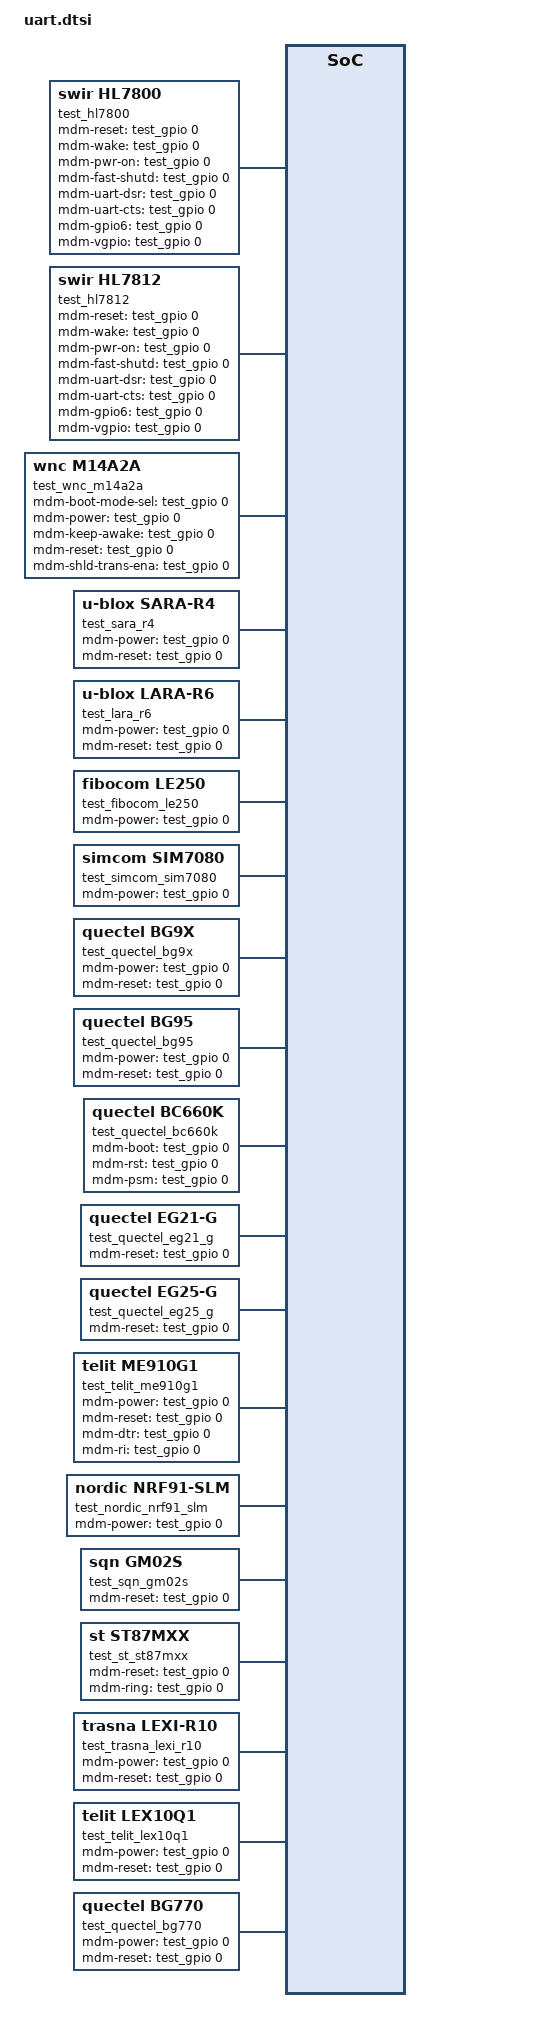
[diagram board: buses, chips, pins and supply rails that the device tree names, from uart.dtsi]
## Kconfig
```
# Copyright (c) 2021 Linaro Limited
# SPDX-License-Identifier: Apache-2.0

source "Kconfig.zephyr"

# Modem Kconfig depends on SERIAL_SUPPORT_INTERRUPT so
# fake out Kconfig for testing purposes.

config TEST_UART
	bool "Test UART"
	select SERIAL_HAS_DRIVER
	select SERIAL_SUPPORT_INTERRUPT
```

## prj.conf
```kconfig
CONFIG_NET_NAMESPACE_COMPAT_MODE=n
```

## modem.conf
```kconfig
CONFIG_TEST=y
CONFIG_TEST_RANDOM_GENERATOR=y
CONFIG_TEST_USERSPACE=y
CONFIG_SERIAL=y
CONFIG_NETWORKING=y
CONFIG_NET_IPV4=y
CONFIG_MODEM=y
CONFIG_MODEM_HL7800=y
CONFIG_MODEM_HL7800_FW_UPDATE=y
CONFIG_MODEM_HL7800_SET_APN_NAME_ON_STARTUP=y
CONFIG_MODEM_HL7800_APN_NAME="internet"
CONFIG_MODEM_HL7800_RAT_M1=y
CONFIG_MODEM_WNCM14A2A=y
```

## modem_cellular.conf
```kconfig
CONFIG_GPIO=y
CONFIG_SERIAL=y
CONFIG_MODEM=y
CONFIG_NETWORKING=y
CONFIG_NET_L2_PPP=y
CONFIG_PM_DEVICE=y
CONFIG_MODEM_CELLULAR=y
CONFIG_UART_ASYNC_API=y
```

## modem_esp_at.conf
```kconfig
CONFIG_GPIO=y
CONFIG_SERIAL=y
CONFIG_MODEM=y
CONFIG_NETWORKING=y
CONFIG_NET_SOCKETS=y
CONFIG_NET_IPV4=y
CONFIG_WIFI=y
CONFIG_WIFI_ESP_AT_CIPDINFO_USE=y
CONFIG_NET_CONNECTION_MANAGER=y
CONFIG_NET_CONNECTION_MANAGER_CONNECTIVITY_WIFI_MGMT=y
```

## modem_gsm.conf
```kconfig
CONFIG_GPIO=y
CONFIG_SERIAL=y
CONFIG_MODEM=y
CONFIG_NETWORKING=y
CONFIG_NET_IPV4=y
CONFIG_NET_DRIVERS=y
CONFIG_NET_PPP=y
CONFIG_NET_L2_PPP=y
CONFIG_MODEM_GSM_PPP=y
```

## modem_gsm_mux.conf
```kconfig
CONFIG_GPIO=y
CONFIG_SERIAL=y
CONFIG_MODEM=y
CONFIG_NETWORKING=y
CONFIG_NET_IPV4=y
CONFIG_NET_DRIVERS=y
CONFIG_NET_PPP=y
CONFIG_NET_L2_PPP=y
CONFIG_MODEM_GSM_PPP=y
CONFIG_GSM_MUX=y
CONFIG_UART_MUX=y
```

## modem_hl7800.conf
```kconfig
CONFIG_GPIO=y
CONFIG_SERIAL=y
CONFIG_MODEM=y
CONFIG_NETWORKING=y
CONFIG_NET_IPV4=y
CONFIG_NET_IPV6=y
CONFIG_MODEM_HL7800=y
CONFIG_MODEM_HL7800_FW_UPDATE=y
CONFIG_MODEM_HL7800_SET_APN_NAME_ON_STARTUP=y
CONFIG_MODEM_HL7800_APN_NAME="internet"
CONFIG_MODEM_HL7800_RAT_M1=y
CONFIG_MODEM_WNCM14A2A=y
```

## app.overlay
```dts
/*
 * Copyright (c) 2020, Linaro Ltd.
 *
 * SPDX-License-Identifier: Apache-2.0
 *
 * Application overlay for testing driver builds
 *
 * Names in this file should be chosen in a way that won't conflict
 * with real-world devicetree nodes, to allow these tests to run on
 * (and be extended to test) real hardware.
 */

/ {
	test {
		#address-cells = <1>;
		#size-cells = <1>;

		test_uart: uart@55556666 {
			compatible = "vnd,serial";
			reg = <0x55556666 0x1000>;
			status = "okay";

#include "uart.dtsi"
		};

		test_gpio: gpio@deadbeef {
			compatible = "vnd,gpio";
			reg = <0xdeadbeef 0x1000>;
			gpio-controller;
			#gpio-cells = <0x2>;
			status = "okay";
		};
	};

	test_sim_mux: test-sim-mux {
		compatible = "gpio-mux";
		#mux-control-cells = <0>;
		#mux-state-cells = <1>;
		mux-gpios = <&test_gpio 1 0>;
	};
};
```

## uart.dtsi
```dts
/*
 * Copyright (c) 2020, Linaro Ltd.
 *
 * SPDX-License-Identifier: Apache-2.0
 *
 * Application overlay for uart devices
 */

test_hl7800: hl7800 {
	compatible = "swir,hl7800";
	mdm-reset-gpios = <&test_gpio 0 0>;
	mdm-wake-gpios = <&test_gpio 0 0>;
	mdm-pwr-on-gpios = <&test_gpio 0 0>;
	mdm-fast-shutd-gpios = <&test_gpio 0 0>;
	mdm-uart-dsr-gpios = <&test_gpio 0 0>;
	mdm-uart-cts-gpios = <&test_gpio 0 0>;
	mdm-gpio6-gpios = <&test_gpio 0 0>;
	mdm-vgpio-gpios = <&test_gpio 0 0>;

	test_hl7800_socket_offload: socket_offload {
		compatible = "swir,hl7800-offload", "swir,hl78xx-offload";
		max-data-length = <512>;
	};

	test_hl7800_gnss: hl_gnss {
		compatible = "swir,hl7800-gnss", "swir,hl78xx-gnss";
		pps-mode = "GNSS_PPS_MODE_DISABLED";
		fix-rate = <1000>;
	};
};

test_hl7812: hl7812 {
	compatible = "swir,hl7812";
	mdm-reset-gpios = <&test_gpio 0 0>;
	mdm-wake-gpios = <&test_gpio 0 0>;
	mdm-pwr-on-gpios = <&test_gpio 0 0>;
	mdm-fast-shutd-gpios = <&test_gpio 0 0>;
	mdm-uart-dsr-gpios = <&test_gpio 0 0>;
	mdm-uart-cts-gpios = <&test_gpio 0 0>;
	mdm-gpio6-gpios = <&test_gpio 0 0>;
	mdm-vgpio-gpios = <&test_gpio 0 0>;

	test_hl7812_socket_offload: socket_offload {
		compatible = "swir,hl7812-offload";
		max-data-length = <512>;
	};

	test_hl7812_gnss: hl_gnss {
		compatible = "swir,hl7812-gnss";
		pps-mode = "GNSS_PPS_MODE_DISABLED";
		fix-rate = <1000>;
	};
};

test_wnc_m14a2a: wncm14a2a {
	compatible = "wnc,m14a2a";
	mdm-boot-mode-sel-gpios = <&test_gpio 0 0>;
	mdm-power-gpios = <&test_gpio 0 0>;
	mdm-keep-awake-gpios = <&test_gpio 0 0>;
	mdm-reset-gpios = <&test_gpio 0 0>;
	mdm-shld-trans-ena-gpios = <&test_gpio 0 0>;
};

test_sara_r4: sara_r4 {
	compatible = "u-blox,sara-r4";

	mdm-power-gpios = <&test_gpio 0 0>;
	mdm-reset-gpios = <&test_gpio 0 0>;
};

test_lara_r6: lara_r6 {
	compatible = "u-blox,lara-r6";

	mdm-power-gpios = <&test_gpio 0 0>;
	mdm-reset-gpios = <&test_gpio 0 0>;
};

test_fibocom_le250: fibocom_le250 {
	compatible = "fibocom,le250";

	mdm-power-gpios = <&test_gpio 0 0>;
};

test_simcom_sim7080: sim7080 {
	compatible = "simcom,sim7080";

	mdm-power-gpios = <&test_gpio 0 0>;
};

test_quectel_bg9x: quectel_bg9x {
	compatible = "quectel,bg9x";

	mdm-power-gpios = <&test_gpio 0 0>;
	mdm-reset-gpios = <&test_gpio 0 0>;
};

test_quectel_bg95: quectel_bg95 {
	compatible = "quectel,bg95";

	mdm-power-gpios = <&test_gpio 0 0>;
	mdm-reset-gpios = <&test_gpio 0 0>;

	sim-slots {
		compatible = "modem-sims";
		#address-cells = <1>;
		#size-cells = <0>;

		sim-slot@0 {
			reg = <0>;
			mux-states = <&test_sim_mux 0>;
		};

		sim-slot@1 {
			reg = <1>;
			mux-states = <&test_sim_mux 1>;
			default-sim;
		};
	};
};

test_quectel_bc660k: bc660k {
	compatible = "quectel,bc660k";

	mdm-boot-gpios = <&test_gpio 0 0>;
	mdm-rst-gpios = <&test_gpio 0 0>;
	mdm-psm-gpios = <&test_gpio 0 0>;
};

test_quectel_eg21_g: quectel_eg21_g {
	compatible = "quectel,eg21-g";

	mdm-reset-gpios = <&test_gpio 0 0>;
};

test_quectel_eg25_g: quectel_eg25_g {
	compatible = "quectel,eg25-g";

	mdm-reset-gpios = <&test_gpio 0 0>;
};

test_telit_me910g1: telit_me910g1 {
	compatible = "telit,me910g1";

	mdm-power-gpios = <&test_gpio 0 0>;
	mdm-reset-gpios = <&test_gpio 0 0>;

	mdm-dtr-gpios = <&test_gpio 0 0>;
	mdm-ri-gpios = <&test_gpio 0 0>;
};

test_esp_at: esp_at {
	compatible = "espressif,esp-at";
};

test_nordic_nrf91_slm: nordic_nrf91_slm {
	compatible = "nordic,nrf91-slm";

	mdm-power-gpios = <&test_gpio 0 0>;
};

test_nordic_nrf91_sm_v2: nordic_nrf91_sm_v2 {
	compatible = "nordic,nrf91-sm-v2";
};

test_sqn_gm02s: sqn_gm02s {
	compatible = "sqn,gm02s";

	mdm-reset-gpios = <&test_gpio 0 0>;
};

test_st_st87mxx: st87mxx {
	compatible = "st,st87mxx";

	mdm-reset-gpios = <&test_gpio 0 0>;
	mdm-ring-gpios = <&test_gpio 0 0>;
};

test_trasna_lexi_r10: trasna_lexi_r10 {
	compatible = "trasna,lexi-r10";

	mdm-power-gpios = <&test_gpio 0 0>;
	mdm-reset-gpios = <&test_gpio 0 0>;
};

test_telit_lex10q1: telit_lex10q1 {
	compatible = "telit,lex10q1";

	mdm-power-gpios = <&test_gpio 0 0>;
	mdm-reset-gpios = <&test_gpio 0 0>;
};

test_quectel_bg770: quectel_bg770 {
	compatible = "quectel,bg770";

	mdm-power-gpios = <&test_gpio 0 0>;
	mdm-reset-gpios = <&test_gpio 0 0>;
};
```

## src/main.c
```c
/*
 * Copyright (c) 2012-2014 Wind River Systems, Inc.
 *
 * SPDX-License-Identifier: Apache-2.0
 */

#include <zephyr/device.h>
#include <zephyr/toolchain.h>

#ifdef CONFIG_MODEM_CELLULAR
#include <zephyr/modem/chat.h>
#include <zephyr/drivers/modem/modem_cellular.h>

/* Validate the board-init registration macro expands, links, and binds a
 * board-supplied chat script to a modem instance.
 */
MODEM_CHAT_MATCH_DEFINE(board_init_ok_match, "OK", "", NULL);
MODEM_CHAT_SCRIPT_CMDS_DEFINE(board_init_script_cmds,
			      MODEM_CHAT_SCRIPT_CMD_RESP("AT", board_init_ok_match));
MODEM_CHAT_SCRIPT_NO_ABORT_DEFINE(board_init_script, board_init_script_cmds, NULL, 4);
MODEM_CELLULAR_BOARD_INIT_DEFINE(DT_NODELABEL(test_quectel_eg25_g), &board_init_script);
#elif defined(CONFIG_MODEM_HL78XX)
#include <zephyr/drivers/modem/hl78xx_apis.h>
#endif /* CONFIG_MODEM_CELLULAR */

int main(void)
{
#ifdef CONFIG_MODEM_CELLULAR
	/* Validate drivers compiled in */
	__maybe_unused const struct device *swir_hl7800 = DEVICE_DT_GET_ONE(swir_hl7800);
	__maybe_unused const struct device *wnc_m14a2a = DEVICE_DT_GET_ONE(wnc_m14a2a);
	__maybe_unused const struct device *u_blox_sara_r4 = DEVICE_DT_GET_ONE(u_blox_sara_r4);
	__maybe_unused const struct device *simcom_sim7080 = DEVICE_DT_GET_ONE(simcom_sim7080);
	__maybe_unused const struct device *quectel_bc660k = DEVICE_DT_GET_ONE(quectel_bc660k);
	__maybe_unused const struct device *quectel_bg9x = DEVICE_DT_GET_ONE(quectel_bg9x);
	__maybe_unused const struct device *quectel_eg25_g = DEVICE_DT_GET_ONE(quectel_eg25_g);
	__maybe_unused const struct device *telit_me910g1 = DEVICE_DT_GET_ONE(telit_me910g1);
	__maybe_unused const struct device *nordic_nrf91_slm = DEVICE_DT_GET_ONE(nordic_nrf91_slm);
	__maybe_unused const struct device *sqn_gm02s = DEVICE_DT_GET_ONE(sqn_gm02s);
	__maybe_unused const struct device *st_st87mxx = DEVICE_DT_GET_ONE(st_st87mxx);
	__maybe_unused const struct device *trasna_lexi_r10 = DEVICE_DT_GET_ONE(trasna_lexi_r10);
	__maybe_unused const struct device *trasna_lexi_r7 = DEVICE_DT_GET_ONE(trasna_lexi_r7);
	__maybe_unused const struct device *quectel_bg770 = DEVICE_DT_GET_ONE(quectel_bg770);

#elif defined(CONFIG_MODEM_HL78XX)
	/** Validate driver compiled in. */

#if DT_HAS_COMPAT_STATUS_OKAY(swir_hl7800)
	__maybe_unused const struct device *swir_hl78xx = DEVICE_DT_GET_ONE(swir_hl7800);
#elif DT_HAS_COMPAT_STATUS_OKAY(swir_hl7802)
	__maybe_unused const struct device *swir_hl78xx = DEVICE_DT_GET_ONE(swir_hl7802);
#elif DT_HAS_COMPAT_STATUS_OKAY(swir_hl7810)
	__maybe_unused const struct device *swir_hl78xx = DEVICE_DT_GET_ONE(swir_hl7810);
#elif DT_HAS_COMPAT_STATUS_OKAY(swir_hl7812)
	__maybe_unused const struct device *swir_hl78xx = DEVICE_DT_GET_ONE(swir_hl7812);
#else
#error "CONFIG_MODEM_HL78XX enabled, but no supported SWIR HL78XX devicetree node has status okay"
#endif

#endif /* CONFIG_MODEM_CELLULAR */
	return 0;
}

#ifdef CONFIG_CONNECTIVITY_WIFI_MGMT_APPLICATION

#include <zephyr/net/conn_mgr_connectivity_impl.h>
#include <zephyr/net/conn_mgr/connectivity_wifi_mgmt.h>

/* Bind L2 connectity APIs. */
static struct conn_mgr_conn_api conn_api = {0};

CONN_MGR_CONN_DEFINE(CONNECTIVITY_WIFI_MGMT, &conn_api);

#endif /* CONFIG_CONNECTIVITY_WIFI_MGMT_APPLICATION */
```
